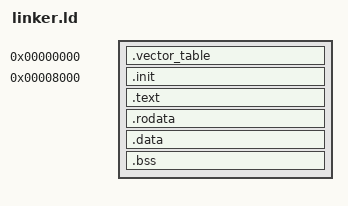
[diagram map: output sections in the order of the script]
/* 
    ======================================================================
    This file is part of FurniOS.

    Copyright (C) 2026 Oliver Arendt (furnio, fkolleg)
    www.fkolleg.de
    info@fkolleg.de

    This program is free software; you can redistribute it and/or
    modify it under the terms of the GNU General Public License
    as published by the Free Software Foundation; either version 3
    of the License, or (at your option) any later version.

    This program is distributed in the hope that it will be useful,
    but WITHOUT ANY WARRANTY; without even the implied warranty of
    MERCHANTABILITY or FITNESS FOR A PARTICULAR PURPOSE. See the
    GNU General Public License for more details.

    You should have received a copy of the GNU General Public License
    along with this program; if not, see
    <https://www.gnu.org/licenses/>.

    Additional restriction:
    This software may not be used, in whole or in part, to train machine 
    learning models (including LLMs) without explicit prior written 
    permission.
    Violations will terminate your rights under this license.

    ======================================================================
*/

ENTRY(reset)
SECTIONS
{
    . = 0x00000000;

    .vector_table : { KEEP(*(.vector_table)) }

	. = 0x00008000;

	.init : { *(.init) }
	.text : { *(.text) }
	.rodata : { *(.rodata) }
	. = ALIGN(1<<20);
	.data : { *(.data) }
	.bss  : { *(.bss)  }
}
